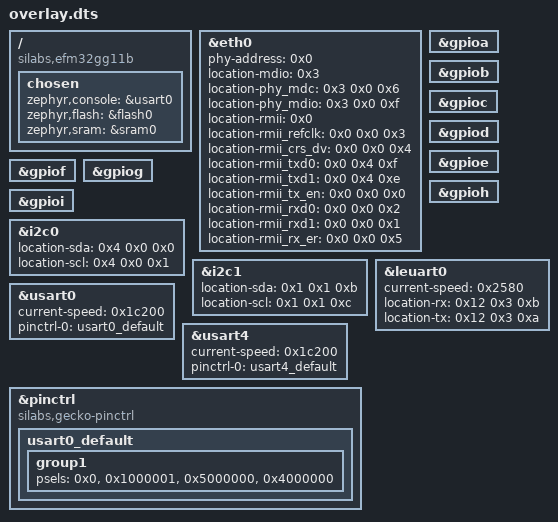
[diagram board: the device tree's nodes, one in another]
/ {
	compatible = "silabs,efm32gg11b", "silabs,efm32gg_slwstk6121a";
	chosen {
		zephyr,console = &usart0;
		zephyr,flash = &flash0;
		zephyr,sram = &sram0;
	};
};
&eth0{
	status = "okay";
	phy-address = < 0x0 >;
	location-mdio = < 0x3 >;
	location-phy_mdc = < 0x3 0x0 0x6 >;
	location-phy_mdio = < 0x3 0x0 0xf >;
	location-rmii = < 0x0 >;
	location-rmii_refclk = < 0x0 0x0 0x3 >;
	location-rmii_crs_dv = < 0x0 0x0 0x4 >;
	location-rmii_txd0 = < 0x0 0x4 0xf >;
	location-rmii_txd1 = < 0x0 0x4 0xe >;
	location-rmii_tx_en = < 0x0 0x0 0x0 >;
	location-rmii_rxd0 = < 0x0 0x0 0x2 >;
	location-rmii_rxd1 = < 0x0 0x0 0x1 >;
	location-rmii_rx_er = < 0x0 0x0 0x5 >;
};
&gpioa{
	status = "okay";
};
&gpiob{
	status = "okay";
};
&gpioc{
	status = "okay";
};
&gpiod{
	status = "okay";
};
&gpioe{
	status = "okay";
};
&gpiof{
	status = "okay";
};
&gpiog{
	status = "okay";
};
&gpioh{
	status = "okay";
};
&gpioi{
	status = "okay";
};
&i2c0{
	status = "okay";
	location-sda = < 0x4 0x0 0x0 >;
	location-scl = < 0x4 0x0 0x1 >;
};
&i2c1{
	status = "okay";
	location-sda = < 0x1 0x1 0xb >;
	location-scl = < 0x1 0x1 0xc >;
};
&leuart0{
	status = "okay";
	current-speed = < 0x2580 >;
	location-rx = < 0x12 0x3 0xb >;
	location-tx = < 0x12 0x3 0xa >;
};
&usart0{
	status = "okay";
	current-speed = < 0x1c200 >;
	pinctrl-0 = < &usart0_default >;
	pinctrl-names = "default";
};
&usart4{
	status = "okay";
	current-speed = < 0x1c200 >;
	pinctrl-0 = < &usart4_default >;
	pinctrl-names = "default";
};
&pinctrl{
	compatible = "silabs,gecko-pinctrl";
	usart0_default: usart0_default {
		group1 {
			psels = < 0x0 >, < 0x1000001 >, < 0x5000000 >, < 0x4000000 >;
		};
	};
};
